# G32F031 register map
File version: 1.0
CPU: CM0PLUS r0p1, little endian, no MPU, no FPU, 2 interrupt priority bits
Registers are 32-bit, read-write, reset 0x0 unless marked. A register's access mark holds for its fields unless they carry their own. Offsets are from the block's base; [hi:lo] are bit positions; {n}, {i} and the like mark numbered series.

## ATMR — Advance timer
Base 0x40000C00
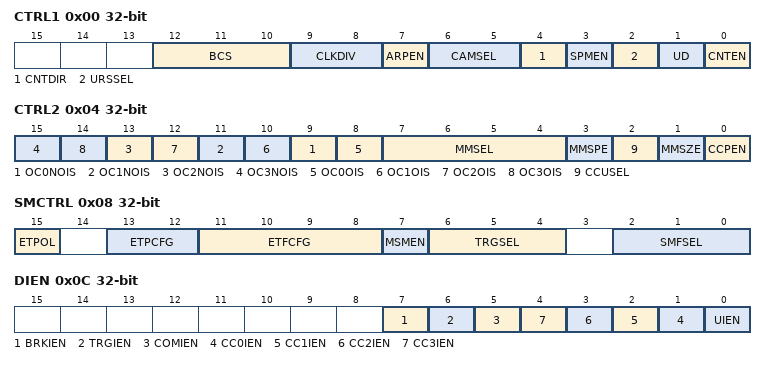
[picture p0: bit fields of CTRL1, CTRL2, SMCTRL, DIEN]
0x00 CTRL1 — control register 1
  [12:10] BCS — BRK Source Selection
  [9:8] CLKDIV — Clock division
  [7] ARPEN — Auto-reload preload enable
  [6:5] CAMSEL — Center-aligned mode selection
  [4] CNTDIR — Direction
  [3] SPMEN — One-pulse mode
  [2] URSSEL — Update request source
  [1] UD — Update disable
  [0] CNTEN — Counter enable
0x04 CTRL2 — control register 2
  [2n+9] OC{n}NOIS (n=0..3) — Output Idle state {n}
  [2n+8] OC{n}OIS (n=0..3) — Output Idle state {n}
  [7:4] MMSEL — Master mode selection
  [3] MMSPE — TRGO Signal is Generated when the Counter Matches the Autoreload Register
  [2] CCUSEL — Capture/compare control update selection
  [1] MMSZE — When the counter returns to 0, TRGO signal is generated
  [0] CCPEN — Capture/compare preloaded control
0x08 SMCTRL — slave mode control register
  [15] ETPOL — External trigger polarity
  [13:12] ETPCFG — External trigger prescaler
  [11:8] ETFCFG — External trigger filter
  [7] MSMEN — Master/Slave mode
  [6:4] TRGSEL — Trigger selection
  [2:0] SMFSEL — Slave mode selection
0x0C DIEN — DMA/Interrupt enable register
  [7] BRKIEN — Break interrupt enable
  [6] TRGIEN — Trigger interrupt enable
  [5] COMIEN — COM interrupt enable
  [n+1] CC{n}IEN (n=0..3) — Capture/Compare {n} interrupt enable
  [0] UIEN — Update interrupt enable
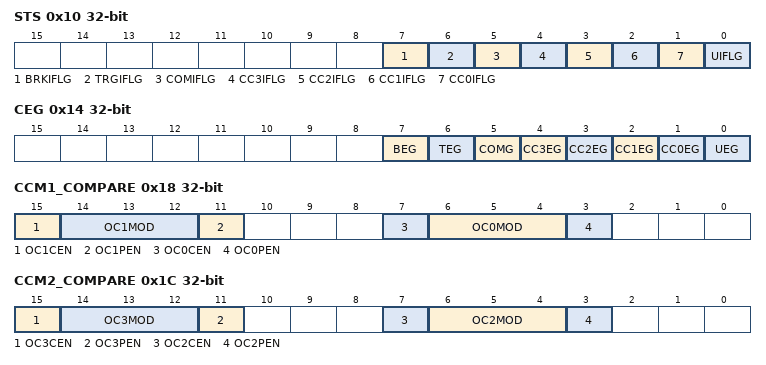
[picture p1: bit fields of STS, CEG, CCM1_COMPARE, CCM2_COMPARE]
0x10 STS — status register
  [7] BRKIFLG — Break interrupt flag
  [6] TRGIFLG — Trigger interrupt flag
  [5] COMIFLG — COM interrupt flag
  [4] CC3IFLG — Capture/Compare 3 interrupt flag
  [3] CC2IFLG — Capture/Compare 2 interrupt flag
  [2] CC1IFLG — Capture/Compare 1 interrupt flag
  [1] CC0IFLG — Capture/compare 0 interrupt flag
  [0] UIFLG — Update interrupt flag
0x14 CEG wo — event generation register
  [7] BEG — Break generation
  [6] TEG — Trigger generation
  [5] COMG — Capture/Compare control update generation
  [n+1] CC{n}EG (n=0..3) — Capture/compare {n} generation
  [0] UEG — Update generation
0x18 CCM1_COMPARE — capture/compare mode register 1 (output mode)
  [15] OC1CEN — Output Compare 1 clear enable
  [14:12] OC1MOD — Output Compare 1 mode
  [11] OC1PEN — Output Compare 1 preload enable
  [7] OC0CEN — Output Compare 0 clear enable
  [6:4] OC0MOD — Output Compare 0 mode
  [3] OC0PEN — Output Compare 0 preload enable
0x1C CCM2_COMPARE — capture/compare mode register 2 (output mode)
  [15] OC3CEN — Output compare 3 clear enable
  [14:12] OC3MOD — Output compare 3 mode
  [11] OC3PEN — Output compare 3 preload enable
  [7] OC2CEN — Output compare 2 clear enable
  [6:4] OC2MOD — Output compare 2 mode
  [3] OC2PEN — Output compare 2 preload enable
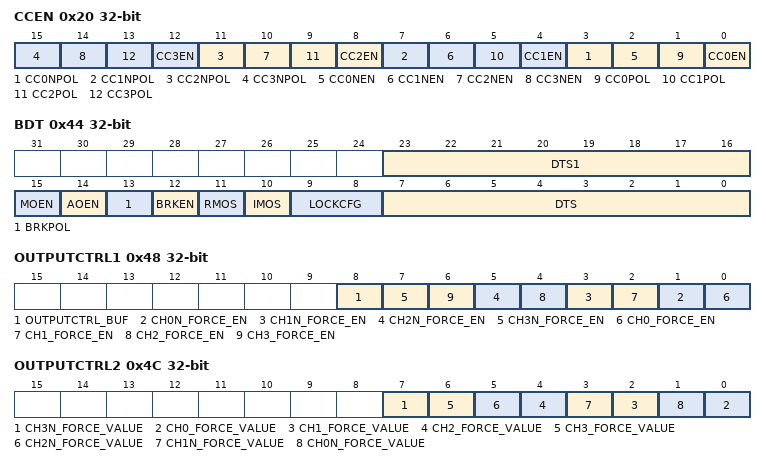
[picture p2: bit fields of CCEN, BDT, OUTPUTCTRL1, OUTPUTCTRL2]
0x20 CCEN — capture/compare enable register
  [4n+3] CC{n}NPOL (n=0..3) — Capture/Compare {n} output Polarity
  [4n+2] CC{n}NEN (n=0..3) — Capture/Compare {n} complementary output enable
  [4n+1] CC{n}POL (n=0..3) — Capture/Compare {n} output Polarity
  [4n] CC{n}EN (n=0..3) — Capture/Compare {n} output enable
0x24 CNT — counter
  [15:0] CNT — counter value
0x28 PSC — prescaler
  [15:0] PSC — Prescaler value
0x2C AUTORLD — auto-reload register
  [15:0] AUTORLD — Auto-reload value
0x30 REPCNT — repetition counter register
  [7:0] REPCNT — Repetition counter value
{0x34+4i} CC{i} (i=0..3) — capture/compare register {i}
  [15:0] CC{i} — Capture/Compare {i} value
0x44 BDT — break and dead-time register
  [23:16] DTS1 — Dead Time Setup
  [15] MOEN — Main output enable
  [14] AOEN — Automatic output enable
  [13] BRKPOL — Break polarity
  [12] BRKEN — Break enable
  [11] RMOS — Off-state selection for Run mode
  [10] IMOS — Off-state selection for Idle mode
  [9:8] LOCKCFG — Lock configuration
  [7:0] DTS — Dead-time generator setup
0x48 OUTPUTCTRL1 — Output ctrl register 1
  [8] OUTPUTCTRL_BUF — Output Control Buffering is Enable
  [2n+1] CH{n}N_FORCE_EN (n=0..3) — Complementary Channel Output Control Enable for Channel {n}
  [2n] CH{n}_FORCE_EN (n=0..3) — Outputs the Control Enable for Channel {n}
0x4C OUTPUTCTRL2 — Output ctrl register 2
  [7] CH3N_FORCE_VALUE — Outputs the Level for Channel 3
  [2n] CH{n}_FORCE_VALUE (n=0..3) — Outputs the Level for Channel {n}
  [5] CH2N_FORCE_VALUE — Complementary Channel Output Level for Channel 2
  [3] CH1N_FORCE_VALUE — Complementary Channel Output Level for Channel 1
  [1] CH0N_FORCE_VALUE — Complementary Channel Output Level for Channel 0
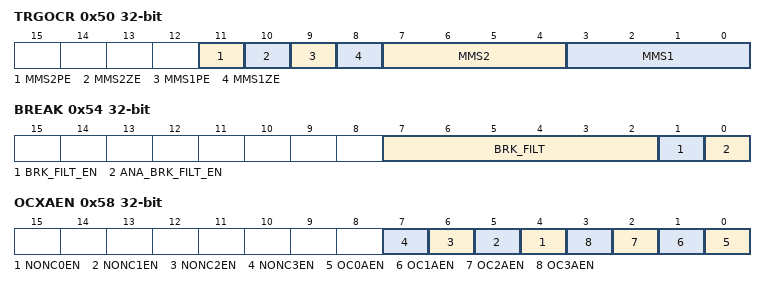
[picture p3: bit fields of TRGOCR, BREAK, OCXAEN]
0x50 TRGOCR — TRGO control register
  [11] MMS2PE — Master mdoe selection 2 generated TRGO1 when return to Autoreload
  [10] MMS2ZE — Master mdoe selection 2 generated TRGO1 when return to 0
  [9] MMS1PE — Master mdoe selection 1 generated TRGO1 when return to Autoreload
  [8] MMS1ZE — Master mdoe selection 1 generated TRGO1 when return to 0
  [7:4] MMS2 — Master mode selection 2
  [3:0] MMS1 — Master mode selection 1
0x54 BREAK — BREAK Filter register
  [7:2] BRK_FILT — Filter coefficient
  [1] BRK_FILT_EN — Break_in Fliter Enable
  [0] ANA_BRK_FILT_EN — Analog Break_in Fliter Enable
0x58 OCXAEN — Lower comparison register control register
  [n+4] NONC{n}EN (n=0..3) — Channel {n} Complementary Independent Selection
  [n] OC{n}AEN (n=0..3) — Channel {n} Asymmetric PWM Output Mode Enable
{0x5C+4i} CC{i}C (i=0..3) — Channel {i} Compare Register
  [15:0] CCR{i}C — Channel {i} Capture/Compare Register Complementary Register
